AUTOSAR XML (schema 00046)
package /EcuExtract
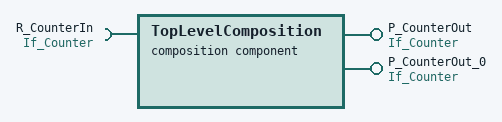
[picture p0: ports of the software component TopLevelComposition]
  composition sw component type TopLevelComposition
    require port R_CounterIn: required-interface=If_Counter
    provide port P_CounterOut: provided-interface=If_Counter
    provide port P_CounterOut_0: provided-interface=If_Counter
    6 x component:
      BswM_Prototype: type=BswM
      ComM_Prototype: type=ComM
      DevelopmentErrorTracer_Prototype: type=DevelopmentErrorTracer
      SWC_ModifyEcho: type=SWC_ModifyEcho
      SWC_CyclicCounter: type=SWC_CyclicCounter
      SWC_IoHwAbs: type=SWC_IoHwAbs
    connect BswM_Prototype.BswM_ModeSwitchPort_BswMSwitchPort_Rte -> SWC_CyclicCounter.ModeSwitchPort_BSWM_COMBINEDACTION_BswMMode_PortInterfaces_BswMMode
    connect ComM_Prototype.UR_ComMUser_0 -> SWC_CyclicCounter.UR_ComMUser_0
    connect DevelopmentErrorTracer_Prototype.DS_SWC_0 -> SWC_CyclicCounter.R_CyclicCounterDet
    delegate SWC_ModifyEcho.R_NewCounterIn <-> outer port R_CounterIn
    delegate SWC_ModifyEcho.P_EchoOut <-> outer port P_CounterOut
    connect SWC_CyclicCounter.P_EchoCalc -> SWC_ModifyEcho.R_EchoResult
    connect SWC_ModifyEcho.P_SpecialRequest -> SWC_CyclicCounter.R_SpecialHandling
    delegate SWC_CyclicCounter.P_CounterOut <-> outer port P_CounterOut_0
    connect SWC_IoHwAbs.P_MyLED -> SWC_CyclicCounter.R_MyLED
  system ECU: category=ECU_EXTRACT, system-version=1.0.0
    system mapping DataMappings_R_CounterIn: sender-receiver-to-signal-mapping{data-element=TopLevelCompositionPrototype.R_CounterIn.CounterValue, system-signal=CounterIn}
    system mapping DataMappings_P_CounterOut: sender-receiver-to-signal-mapping{data-element=TopLevelCompositionPrototype.P_CounterOut.CounterValue, system-signal=CounterOut}
    system mapping DataMappings_P_CounterOut_0: sender-receiver-to-signal-mapping{data-element=TopLevelCompositionPrototype.P_CounterOut_0.CounterValue, system-signal=CounterOut}
    root-software-compositions:
      root sw composition prototype TopLevelCompositionPrototype: flat-map=FlatMap, software-composition=TopLevelComposition
  flat map FlatMap
    30 x flat instance descriptor:
      BswM_Prototype_0: upstream-reference=TopLevelComposition.BswM_Prototype, ecu-extract-reference=TopLevelCompositionPrototype.BswM_Prototype
      BswM_ModeSwitchPort_BswMSwitchPort_Rte_1: upstream-reference=TopLevelComposition.BswM_Prototype.BswM_ModeSwitchPort_BswMSwitchPort_Rte, ecu-extract-reference=TopLevelCompositionPrototype.BswM_Prototype.BswM_ModeSwitchPort_BswMSwitchPort_Rte
      ComM_Prototype_2: upstream-reference=TopLevelComposition.ComM_Prototype, ecu-extract-reference=TopLevelCompositionPrototype.ComM_Prototype
      UM_ComMUser_0_3: upstream-reference=TopLevelComposition.ComM_Prototype.UM_ComMUser_0, ecu-extract-reference=TopLevelCompositionPrototype.ComM_Prototype.UM_ComMUser_0
      UR_ComMUser_0_4: upstream-reference=TopLevelComposition.ComM_Prototype.UR_ComMUser_0, ecu-extract-reference=TopLevelCompositionPrototype.ComM_Prototype.UR_ComMUser_0
      DevelopmentErrorTracer_Prototype_5: upstream-reference=TopLevelComposition.DevelopmentErrorTracer_Prototype, ecu-extract-reference=TopLevelCompositionPrototype.DevelopmentErrorTracer_Prototype
      DS_SWC_0_6: upstream-reference=TopLevelComposition.DevelopmentErrorTracer_Prototype.DS_SWC_0, ecu-extract-reference=TopLevelCompositionPrototype.DevelopmentErrorTracer_Prototype.DS_SWC_0
      SWC_ModifyEcho_7: upstream-reference=TopLevelComposition.SWC_ModifyEcho, ecu-extract-reference=TopLevelCompositionPrototype.SWC_ModifyEcho
      R_EchoResult_8: upstream-reference=TopLevelComposition.SWC_ModifyEcho.R_EchoResult, ecu-extract-reference=TopLevelCompositionPrototype.SWC_ModifyEcho.R_EchoResult
      R_NewCounterIn_9: upstream-reference=TopLevelComposition.SWC_ModifyEcho.R_NewCounterIn, ecu-extract-reference=TopLevelCompositionPrototype.SWC_ModifyEcho.R_NewCounterIn
      CounterValue_10: upstream-reference=TopLevelComposition.SWC_ModifyEcho.R_NewCounterIn.CounterValue, ecu-extract-reference=TopLevelCompositionPrototype.SWC_ModifyEcho.R_NewCounterIn.CounterValue
      P_EchoOut_11: upstream-reference=TopLevelComposition.SWC_ModifyEcho.P_EchoOut, ecu-extract-reference=TopLevelCompositionPrototype.SWC_ModifyEcho.P_EchoOut
      CounterValue_12: upstream-reference=TopLevelComposition.SWC_ModifyEcho.P_EchoOut.CounterValue, ecu-extract-reference=TopLevelCompositionPrototype.SWC_ModifyEcho.P_EchoOut.CounterValue
      P_SpecialRequest_13: upstream-reference=TopLevelComposition.SWC_ModifyEcho.P_SpecialRequest, ecu-extract-reference=TopLevelCompositionPrototype.SWC_ModifyEcho.P_SpecialRequest
      EventMessage_14: upstream-reference=TopLevelComposition.SWC_ModifyEcho.P_SpecialRequest.EventMessage, ecu-extract-reference=TopLevelCompositionPrototype.SWC_ModifyEcho.P_SpecialRequest.EventMessage
      SWC_CyclicCounter_15: upstream-reference=TopLevelComposition.SWC_CyclicCounter, ecu-extract-reference=TopLevelCompositionPrototype.SWC_CyclicCounter
      P_EchoCalc_16: upstream-reference=TopLevelComposition.SWC_CyclicCounter.P_EchoCalc, ecu-extract-reference=TopLevelCompositionPrototype.SWC_CyclicCounter.P_EchoCalc
      P_CounterOut_17: upstream-reference=TopLevelComposition.SWC_CyclicCounter.P_CounterOut, ecu-extract-reference=TopLevelCompositionPrototype.SWC_CyclicCounter.P_CounterOut
      CounterValue_18: upstream-reference=TopLevelComposition.SWC_CyclicCounter.P_CounterOut.CounterValue, ecu-extract-reference=TopLevelCompositionPrototype.SWC_CyclicCounter.P_CounterOut.CounterValue
      R_MyLED_19: upstream-reference=TopLevelComposition.SWC_CyclicCounter.R_MyLED, ecu-extract-reference=TopLevelCompositionPrototype.SWC_CyclicCounter.R_MyLED
      R_CyclicCounterDet_20: upstream-reference=TopLevelComposition.SWC_CyclicCounter.R_CyclicCounterDet, ecu-extract-reference=TopLevelCompositionPrototype.SWC_CyclicCounter.R_CyclicCounterDet
      R_SpecialHandling_21: upstream-reference=TopLevelComposition.SWC_CyclicCounter.R_SpecialHandling, ecu-extract-reference=TopLevelCompositionPrototype.SWC_CyclicCounter.R_SpecialHandling
      EventMessage_22: upstream-reference=TopLevelComposition.SWC_CyclicCounter.R_SpecialHandling.EventMessage, ecu-extract-reference=TopLevelCompositionPrototype.SWC_CyclicCounter.R_SpecialHandling.EventMessage
      PS_PersistentCounterValue_23: upstream-reference=TopLevelComposition.SWC_CyclicCounter.PS_PersistentCounterValue, ecu-extract-reference=TopLevelCompositionPrototype.SWC_CyclicCounter.PS_PersistentCounterValue
      UR_ComMUser_0_24: upstream-reference=TopLevelComposition.SWC_CyclicCounter.UR_ComMUser_0, ecu-extract-reference=TopLevelCompositionPrototype.SWC_CyclicCounter.UR_ComMUser_0
      ModeSwitchPort_BSWM_COMBINEDACTION_BswMMode_PortInterfaces_BswMMode_25: upstream-reference=TopLevelComposition.SWC_CyclicCounter.ModeSwitchPort_BSWM_COMBINEDACTION_BswMMode_PortInterfaces_BswMMode, ecu-extract-reference=TopLevelCompositionPrototype.SWC_CyclicCounter.ModeSwitchPort_BSWM_COMBINEDACTION_BswMMode_PortInterfaces_BswMMode
      CurrentCounterValue_26: upstream-reference=TopLevelComposition.SWC_CyclicCounter.CurrentCounterValue, ecu-extract-reference=TopLevelCompositionPrototype.SWC_CyclicCounter.CurrentCounterValue
      PrmCounterValue_27: upstream-reference=TopLevelComposition.SWC_CyclicCounter.PrmCounterValue, ecu-extract-reference=TopLevelCompositionPrototype.SWC_CyclicCounter.PrmCounterValue
      SWC_IoHwAbs_28: upstream-reference=TopLevelComposition.SWC_IoHwAbs, ecu-extract-reference=TopLevelCompositionPrototype.SWC_IoHwAbs
      P_MyLED_29: upstream-reference=TopLevelComposition.SWC_IoHwAbs.P_MyLED, ecu-extract-reference=TopLevelCompositionPrototype.SWC_IoHwAbs.P_MyLED
